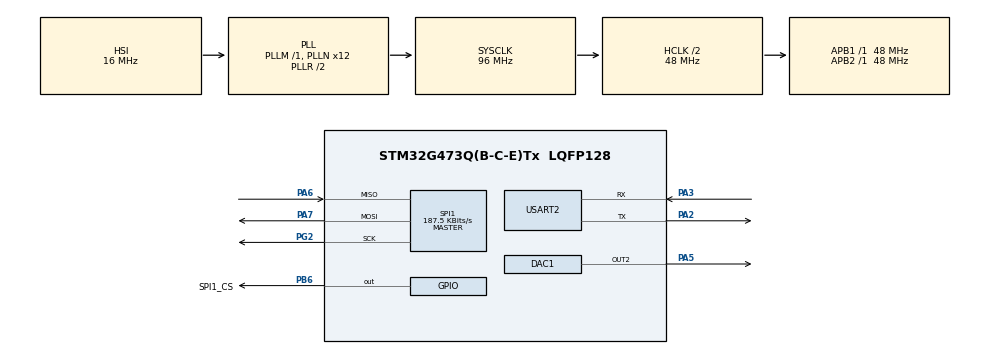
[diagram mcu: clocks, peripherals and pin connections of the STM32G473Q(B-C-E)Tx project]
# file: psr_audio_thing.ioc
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DAC1.DAC_Channel-DAC_OUT2=DAC_CHANNEL_2
Mcu.Family=STM32G4
Mcu.Name=STM32G473Q(B-C-E)Tx
Mcu.Package=LQFP128
NVIC.PriorityGroup=NVIC_PRIORITYGROUP_4
PA13.Mode=Serial_Wire
PA13.Signal=SYS_JTMS-SWDIO
PA14.Mode=Serial_Wire
PA14.Signal=SYS_JTCK-SWCLK
PA2.Mode=Asynchronous
PA2.Signal=USART2_TX
PA3.Mode=Asynchronous
PA3.Signal=USART2_RX
PA5.Signal=COMP_DAC12_group
PA6.GPIO_PuPd=GPIO_PULLUP
PA6.Mode=Full_Duplex_Master
PA6.Signal=SPI1_MISO
PA7.GPIO_PuPd=GPIO_PULLUP
PA7.Mode=Full_Duplex_Master
PA7.Signal=SPI1_MOSI
PB6.GPIO_Label=SPI1_CS
PB6.GPIO_PuPd=GPIO_PULLUP
PB6.PinState=GPIO_PIN_SET
PB6.Signal=GPIO_Output
PG2.GPIO_PuPd=GPIO_PULLUP
PG2.Mode=Full_Duplex_Master
PG2.Signal=SPI1_SCK
ProjectManager.HeapSize=0x200
ProjectManager.StackSize=0x400
ProjectManager.TargetToolchain=STM32CubeIDE
RCC.ADC12Freq_Value=96000000
RCC.ADC345Freq_Value=96000000
RCC.AHBCLKDivider=RCC_SYSCLK_DIV2
RCC.AHBFreq_Value=48000000
RCC.APB1Freq_Value=48000000
RCC.APB1TimFreq_Value=48000000
RCC.APB2Freq_Value=48000000
RCC.APB2TimFreq_Value=48000000
RCC.CortexFreq_Value=48000000
RCC.EXTERNAL_CLOCK_VALUE=12288000
RCC.HCLKFreq_Value=48000000
RCC.HSE_VALUE=8000000
RCC.HSI48_VALUE=48000000
RCC.HSI_VALUE=16000000
RCC.LSE_VALUE=32768
RCC.PLLN=12
RCC.SYSCLKFreq_VALUE=96000000
RCC.SYSCLKSource=RCC_SYSCLKSOURCE_PLLCLK
RCC.USBFreq_Value=96000000
RCC.VCOOutputFreq_Value=192000000
SH.COMP_DAC12_group.0=DAC1_OUT2,DAC_OUT2
SPI1.BaudRatePrescaler=SPI_BAUDRATEPRESCALER_256
SPI1.CalculateBaudRate=187.5 KBits/s
SPI1.Direction=SPI_DIRECTION_2LINES
SPI1.Mode=SPI_MODE_MASTER
SPI1.VirtualType=VM_MASTER
USART2.VirtualMode-Asynchronous=VM_ASYNC
VP_FATFS_VS_Generic.Mode=User_defined
VP_SYS_VS_DBSignals.Mode=DisableDeadBatterySignals
board=B-G473E-ZEST1S

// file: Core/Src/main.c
/* USER CODE BEGIN Header */
/**
  ******************************************************************************
  * @file           : main.c
  * @brief          : Main program body
  ******************************************************************************
  * @attention
  *
  * Copyright (c) 2025 STMicroelectronics.
  * All rights reserved.
  *
  * This software is licensed under terms that can be found in the LICENSE file
  * in the root directory of this software component.
  * If no LICENSE file comes with this software, it is provided AS-IS.
  *
  ******************************************************************************
  */
/* USER CODE END Header */
#include "main.h"
#include "app_fatfs.h"

/* USER CODE BEGIN PD */
#define DMA_BUFFER_SIZE 32
#define SAMPLE_FREQ 1000
#define OUTPUT_MID 2048

/* USER CODE END PD */

DAC_HandleTypeDef hdac1;

SPI_HandleTypeDef hspi1;

UART_HandleTypeDef huart2;

void SystemClock_Config(void);
static void MX_GPIO_Init(void);
static void MX_SPI1_Init(void);
static void MX_USART2_UART_Init(void);
static void MX_DAC1_Init(void);

int main(void)
{

  /* MCU Configuration--------------------------------------------------------*/

  /* Reset of all peripherals, Initializes the Flash interface and the Systick. */
  HAL_Init();

  /* Configure the system clock */
  SystemClock_Config();

  /* Initialize all configured peripherals */
  MX_GPIO_Init();
  MX_SPI1_Init();
  MX_USART2_UART_Init();
  if (MX_FATFS_Init() != APP_OK) {
    Error_Handler();
  }
  MX_DAC1_Init();

  /* Infinite loop */
  while (1)
  {

  }
}

void SystemClock_Config(void)
{
  RCC_OscInitTypeDef RCC_OscInitStruct = {0};
  RCC_ClkInitTypeDef RCC_ClkInitStruct = {0};

  /** Configure the main internal regulator output voltage
  */
  HAL_PWREx_ControlVoltageScaling(PWR_REGULATOR_VOLTAGE_SCALE1);

  /** Initializes the RCC Oscillators according to the specified parameters
  * in the RCC_OscInitTypeDef structure.
  */
  RCC_OscInitStruct.OscillatorType = RCC_OSCILLATORTYPE_HSI;
  RCC_OscInitStruct.HSIState = RCC_HSI_ON;
  RCC_OscInitStruct.HSICalibrationValue = RCC_HSICALIBRATION_DEFAULT;
  RCC_OscInitStruct.PLL.PLLState = RCC_PLL_ON;
  RCC_OscInitStruct.PLL.PLLSource = RCC_PLLSOURCE_HSI;
  RCC_OscInitStruct.PLL.PLLM = RCC_PLLM_DIV1;
  RCC_OscInitStruct.PLL.PLLN = 12;
  RCC_OscInitStruct.PLL.PLLP = RCC_PLLP_DIV2;
  RCC_OscInitStruct.PLL.PLLQ = RCC_PLLQ_DIV2;
  RCC_OscInitStruct.PLL.PLLR = RCC_PLLR_DIV2;
  if (HAL_RCC_OscConfig(&RCC_OscInitStruct) != HAL_OK)
  {
    Error_Handler();
  }

  /** Initializes the CPU, AHB and APB buses clocks
  */
  RCC_ClkInitStruct.ClockType = RCC_CLOCKTYPE_HCLK|RCC_CLOCKTYPE_SYSCLK
                              |RCC_CLOCKTYPE_PCLK1|RCC_CLOCKTYPE_PCLK2;
  RCC_ClkInitStruct.SYSCLKSource = RCC_SYSCLKSOURCE_PLLCLK;
  RCC_ClkInitStruct.AHBCLKDivider = RCC_SYSCLK_DIV2;
  RCC_ClkInitStruct.APB1CLKDivider = RCC_HCLK_DIV1;
  RCC_ClkInitStruct.APB2CLKDivider = RCC_HCLK_DIV1;

  if (HAL_RCC_ClockConfig(&RCC_ClkInitStruct, FLASH_LATENCY_1) != HAL_OK)
  {
    Error_Handler();
  }
}

static void MX_DAC1_Init(void)
{

  DAC_ChannelConfTypeDef sConfig = {0};

  /** DAC Initialization
  */
  hdac1.Instance = DAC1;
  if (HAL_DAC_Init(&hdac1) != HAL_OK)
  {
    Error_Handler();
  }

  /** DAC channel OUT2 config
  */
  sConfig.DAC_HighFrequency = DAC_HIGH_FREQUENCY_INTERFACE_MODE_AUTOMATIC;
  sConfig.DAC_DMADoubleDataMode = DISABLE;
  sConfig.DAC_SignedFormat = DISABLE;
  sConfig.DAC_SampleAndHold = DAC_SAMPLEANDHOLD_DISABLE;
  sConfig.DAC_Trigger = DAC_TRIGGER_NONE;
  sConfig.DAC_Trigger2 = DAC_TRIGGER_NONE;
  sConfig.DAC_OutputBuffer = DAC_OUTPUTBUFFER_ENABLE;
  sConfig.DAC_ConnectOnChipPeripheral = DAC_CHIPCONNECT_EXTERNAL;
  sConfig.DAC_UserTrimming = DAC_TRIMMING_FACTORY;
  if (HAL_DAC_ConfigChannel(&hdac1, &sConfig, DAC_CHANNEL_2) != HAL_OK)
  {
    Error_Handler();
  }

}

static void MX_SPI1_Init(void)
{

  /* SPI1 parameter configuration*/
  hspi1.Instance = SPI1;
  hspi1.Init.Mode = SPI_MODE_MASTER;
  hspi1.Init.Direction = SPI_DIRECTION_2LINES;
  hspi1.Init.DataSize = SPI_DATASIZE_4BIT;
  hspi1.Init.CLKPolarity = SPI_POLARITY_LOW;
  hspi1.Init.CLKPhase = SPI_PHASE_1EDGE;
  hspi1.Init.NSS = SPI_NSS_SOFT;
  hspi1.Init.BaudRatePrescaler = SPI_BAUDRATEPRESCALER_256;
  hspi1.Init.FirstBit = SPI_FIRSTBIT_MSB;
  hspi1.Init.TIMode = SPI_TIMODE_DISABLE;
  hspi1.Init.CRCCalculation = SPI_CRCCALCULATION_DISABLE;
  hspi1.Init.CRCPolynomial = 7;
  hspi1.Init.CRCLength = SPI_CRC_LENGTH_DATASIZE;
  hspi1.Init.NSSPMode = SPI_NSS_PULSE_ENABLE;
  if (HAL_SPI_Init(&hspi1) != HAL_OK)
  {
    Error_Handler();
  }

}

static void MX_USART2_UART_Init(void)
{

  huart2.Instance = USART2;
  huart2.Init.BaudRate = 115200;
  huart2.Init.WordLength = UART_WORDLENGTH_8B;
  huart2.Init.StopBits = UART_STOPBITS_1;
  huart2.Init.Parity = UART_PARITY_NONE;
  huart2.Init.Mode = UART_MODE_TX_RX;
  huart2.Init.HwFlowCtl = UART_HWCONTROL_NONE;
  huart2.Init.OverSampling = UART_OVERSAMPLING_16;
  huart2.Init.OneBitSampling = UART_ONE_BIT_SAMPLE_DISABLE;
  huart2.Init.ClockPrescaler = UART_PRESCALER_DIV1;
  huart2.AdvancedInit.AdvFeatureInit = UART_ADVFEATURE_NO_INIT;
  if (HAL_UART_Init(&huart2) != HAL_OK)
  {
    Error_Handler();
  }
  if (HAL_UARTEx_SetTxFifoThreshold(&huart2, UART_TXFIFO_THRESHOLD_1_8) != HAL_OK)
  {
    Error_Handler();
  }
  if (HAL_UARTEx_SetRxFifoThreshold(&huart2, UART_RXFIFO_THRESHOLD_1_8) != HAL_OK)
  {
    Error_Handler();
  }
  if (HAL_UARTEx_DisableFifoMode(&huart2) != HAL_OK)
  {
    Error_Handler();
  }

}

static void MX_GPIO_Init(void)
{
  GPIO_InitTypeDef GPIO_InitStruct = {0};

  /* GPIO Ports Clock Enable */
  __HAL_RCC_GPIOA_CLK_ENABLE();
  __HAL_RCC_GPIOG_CLK_ENABLE();
  __HAL_RCC_GPIOB_CLK_ENABLE();

  /*Configure GPIO pin Output Level */
  HAL_GPIO_WritePin(SPI1_CS_GPIO_Port, SPI1_CS_Pin, GPIO_PIN_SET);

  /*Configure GPIO pin : SPI1_CS_Pin */
  GPIO_InitStruct.Pin = SPI1_CS_Pin;
  GPIO_InitStruct.Mode = GPIO_MODE_OUTPUT_PP;
  GPIO_InitStruct.Pull = GPIO_PULLUP;
  GPIO_InitStruct.Speed = GPIO_SPEED_FREQ_LOW;
  HAL_GPIO_Init(SPI1_CS_GPIO_Port, &GPIO_InitStruct);

}

/* USER CODE BEGIN 4 */
void selectFileAndPlay() {
    char filenames[16][20] = {       // rename to the actual names
        "file1.wav", "file2.wav", "file3.wav", "file4.wav",
        "file5.wav", "file6.wav", "file7.wav", "file8.wav",
        "file9.wav", "file10.wav", "file11.wav", "file12.wav",
        "file13.wav", "file14.wav", "file15.wav", "file16.wav"
    };

    static int fileIndex = HAL_GPIO_ReadPin(GPIOx, GPIO_PIN_8);  // based off of the 4 bit integer from dial

    playAudio(filenames[fileIndex]);  // play audio file

      // Move to next file for next press
}
/* USER CODE END 4 */

void Error_Handler(void)
{
  __disable_irq();
  while (1)
  {
  }
}
